# M2Sxxx register map
Vendor: Microsemi; Series: SmartFusion2; File version: 2.0.32
CPU: CM3 r2p1, little endian, MPU, no FPU, 4 interrupt priority bits
Registers are 32-bit, read-write, no defined reset value unless marked. A register's access mark holds for its fields unless they carry their own. Offsets are from the block's base; [hi:lo] are bit positions; {n}, {i} and the like mark numbered series.

## System_Registers — No description provided for this peripheral
Base 0x40038000
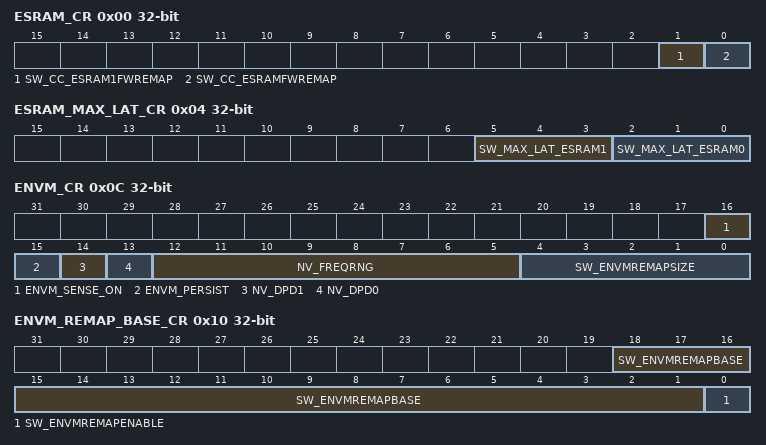
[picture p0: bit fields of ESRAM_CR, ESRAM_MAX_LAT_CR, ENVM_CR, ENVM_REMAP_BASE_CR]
0x00 ESRAM_CR — No description provided for this register
  [1] SW_CC_ESRAM1FWREMAP — No description provided for this field
  [0] SW_CC_ESRAMFWREMAP — No description provided for this field
0x04 ESRAM_MAX_LAT_CR — No description provided for this register
  [5:3] SW_MAX_LAT_ESRAM1 — No description provided for this field
  [2:0] SW_MAX_LAT_ESRAM0 — No description provided for this field
0x08 DDR_CR — No description provided for this register
  [0] SW_CC_DDRFWREMAP — No description provided for this field
0x0C ENVM_CR — No description provided for this register
  [16] ENVM_SENSE_ON — No description provided for this field
  [15] ENVM_PERSIST — No description provided for this field
  [14] NV_DPD1 — No description provided for this field
  [13] NV_DPD0 — No description provided for this field
  [12:5] NV_FREQRNG — No description provided for this field
  [4:0] SW_ENVMREMAPSIZE — No description provided for this field
0x10 ENVM_REMAP_BASE_CR — No description provided for this register
  [18:1] SW_ENVMREMAPBASE — No description provided for this field
  [0] SW_ENVMREMAPENABLE — No description provided for this field
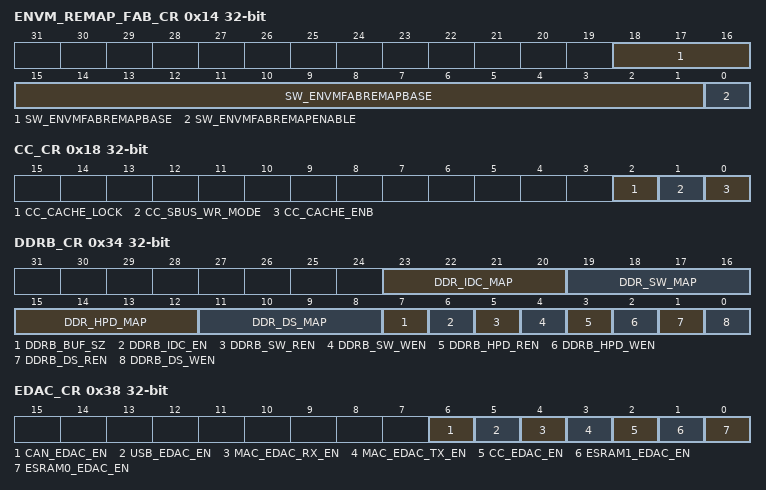
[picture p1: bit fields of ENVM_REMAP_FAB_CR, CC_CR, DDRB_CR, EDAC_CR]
0x14 ENVM_REMAP_FAB_CR — No description provided for this register
  [18:1] SW_ENVMFABREMAPBASE — No description provided for this field
  [0] SW_ENVMFABREMAPENABLE — No description provided for this field
0x18 CC_CR — No description provided for this register
  [2] CC_CACHE_LOCK — No description provided for this field
  [1] CC_SBUS_WR_MODE — No description provided for this field
  [0] CC_CACHE_ENB — No description provided for this field
0x1C CC_REGION_CR — No description provided for this register
  [3:0] CC_CACHE_REGION — No description provided for this field
0x20 CC_LOCK_BASE_ADDR_CR — No description provided for this register
  [18:0] CC_LOCK_BASEADD — No description provided for this field
0x24 CC_FLUSH_INDX_CR — No description provided for this register
  [5:0] CC_FLUSH_INDEX — No description provided for this field
0x28 DDRB_BUF_TIMER_CR — No description provided for this register
  [9:0] DDRB_TIMER — No description provided for this field
0x2C DDRB_NB_ADDR_CR — No description provided for this register
  [15:0] DDRB_NB_ADDR — No description provided for this field
0x30 DDRB_NB_SIZE_CR — No description provided for this register
  [3:0] DDRB_NB_SZ — No description provided for this field
0x34 DDRB_CR — No description provided for this register
  [23:20] DDR_IDC_MAP — No description provided for this field
  [19:16] DDR_SW_MAP — No description provided for this field
  [15:12] DDR_HPD_MAP — No description provided for this field
  [11:8] DDR_DS_MAP — No description provided for this field
  [7] DDRB_BUF_SZ — No description provided for this field
  [6] DDRB_IDC_EN — No description provided for this field
  [5] DDRB_SW_REN — No description provided for this field
  [4] DDRB_SW_WEN — No description provided for this field
  [3] DDRB_HPD_REN — No description provided for this field
  [2] DDRB_HPD_WEN — No description provided for this field
  [1] DDRB_DS_REN — No description provided for this field
  [0] DDRB_DS_WEN — No description provided for this field
0x38 EDAC_CR — No description provided for this register
  [6] CAN_EDAC_EN — No description provided for this field
  [5] USB_EDAC_EN — No description provided for this field
  [4] MAC_EDAC_RX_EN — No description provided for this field
  [3] MAC_EDAC_TX_EN — No description provided for this field
  [2] CC_EDAC_EN — No description provided for this field
  [1] ESRAM1_EDAC_EN — No description provided for this field
  [0] ESRAM0_EDAC_EN — No description provided for this field
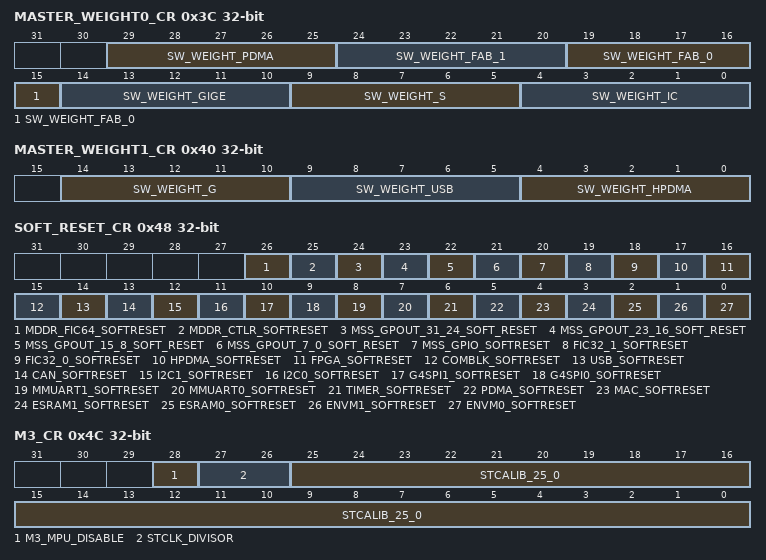
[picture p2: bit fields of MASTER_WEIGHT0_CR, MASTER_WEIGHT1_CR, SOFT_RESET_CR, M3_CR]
0x3C MASTER_WEIGHT0_CR — No description provided for this register
  [29:25] SW_WEIGHT_PDMA — No description provided for this field
  [24:20] SW_WEIGHT_FAB_1 — No description provided for this field
  [19:15] SW_WEIGHT_FAB_0 — No description provided for this field
  [14:10] SW_WEIGHT_GIGE — No description provided for this field
  [9:5] SW_WEIGHT_S — No description provided for this field
  [4:0] SW_WEIGHT_IC — No description provided for this field
0x40 MASTER_WEIGHT1_CR — No description provided for this register
  [14:10] SW_WEIGHT_G — No description provided for this field
  [9:5] SW_WEIGHT_USB — No description provided for this field
  [4:0] SW_WEIGHT_HPDMA — No description provided for this field
0x44 SOFT_IRQ_CR — No description provided for this register
  [0] SOFTINTERRUPT — No description provided for this field
0x48 SOFT_RESET_CR — No description provided for this register
  [26] MDDR_FIC64_SOFTRESET — No description provided for this field
  [25] MDDR_CTLR_SOFTRESET — No description provided for this field
  [24] MSS_GPOUT_31_24_SOFT_RESET — No description provided for this field
  [23] MSS_GPOUT_23_16_SOFT_RESET — No description provided for this field
  [22] MSS_GPOUT_15_8_SOFT_RESET — No description provided for this field
  [21] MSS_GPOUT_7_0_SOFT_RESET — No description provided for this field
  [20] MSS_GPIO_SOFTRESET — No description provided for this field
  [19] FIC32_1_SOFTRESET — No description provided for this field
  [18] FIC32_0_SOFTRESET — No description provided for this field
  [17] HPDMA_SOFTRESET — No description provided for this field
  [16] FPGA_SOFTRESET — No description provided for this field
  [15] COMBLK_SOFTRESET — No description provided for this field
  [14] USB_SOFTRESET — No description provided for this field
  [13] CAN_SOFTRESET — No description provided for this field
  [12] I2C1_SOFTRESET — No description provided for this field
  [11] I2C0_SOFTRESET — No description provided for this field
  [10] G4SPI1_SOFTRESET — No description provided for this field
  [9] G4SPI0_SOFTRESET — No description provided for this field
  [8] MMUART1_SOFTRESET — No description provided for this field
  [7] MMUART0_SOFTRESET — No description provided for this field
  [6] TIMER_SOFTRESET — No description provided for this field
  [5] PDMA_SOFTRESET — No description provided for this field
  [4] MAC_SOFTRESET — No description provided for this field
  [3] ESRAM1_SOFTRESET — No description provided for this field
  [2] ESRAM0_SOFTRESET — No description provided for this field
  [1] ENVM1_SOFTRESET — No description provided for this field
  [0] ENVM0_SOFTRESET — No description provided for this field
0x4C M3_CR — No description provided for this register
  [28] M3_MPU_DISABLE — No description provided for this field
  [27:26] STCLK_DIVISOR — No description provided for this field
  [25:0] STCALIB_25_0 — No description provided for this field
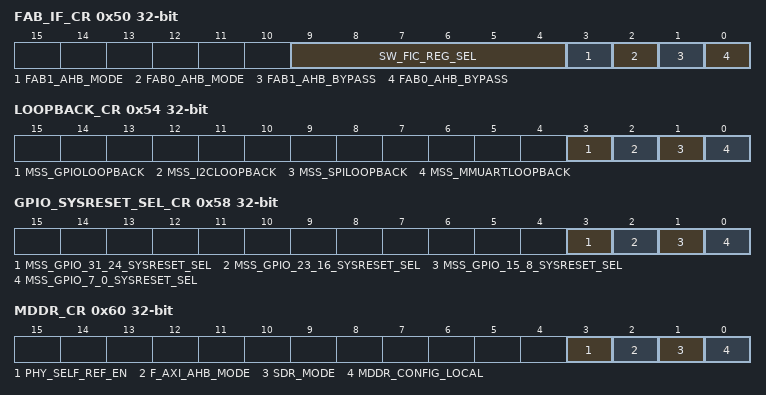
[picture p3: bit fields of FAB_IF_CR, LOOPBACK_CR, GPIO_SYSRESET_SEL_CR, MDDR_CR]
0x50 FAB_IF_CR — No description provided for this register
  [9:4] SW_FIC_REG_SEL — No description provided for this field
  [3] FAB1_AHB_MODE — No description provided for this field
  [2] FAB0_AHB_MODE — No description provided for this field
  [1] FAB1_AHB_BYPASS — No description provided for this field
  [0] FAB0_AHB_BYPASS — No description provided for this field
0x54 LOOPBACK_CR — No description provided for this register
  [3] MSS_GPIOLOOPBACK — No description provided for this field
  [2] MSS_I2CLOOPBACK — No description provided for this field
  [1] MSS_SPILOOPBACK — No description provided for this field
  [0] MSS_MMUARTLOOPBACK — No description provided for this field
0x58 GPIO_SYSRESET_SEL_CR — No description provided for this register
  [3] MSS_GPIO_31_24_SYSRESET_SEL — No description provided for this field
  [2] MSS_GPIO_23_16_SYSRESET_SEL — No description provided for this field
  [1] MSS_GPIO_15_8_SYSRESET_SEL — No description provided for this field
  [0] MSS_GPIO_7_0_SYSRESET_SEL — No description provided for this field
0x5C GPIN_SRC_SEL_CR — No description provided for this register
  [31:0] MSS_GPINSOURCE — No description provided for this field
0x60 MDDR_CR — No description provided for this register
  [3] PHY_SELF_REF_EN — No description provided for this field
  [2] F_AXI_AHB_MODE — No description provided for this field
  [1] SDR_MODE — No description provided for this field
  [0] MDDR_CONFIG_LOCAL — No description provided for this field
0x64 USB_IO_INPUT_SEL_CR — No description provided for this register
  [1:0] USB_IO_INPUT_SEL — No description provided for this field
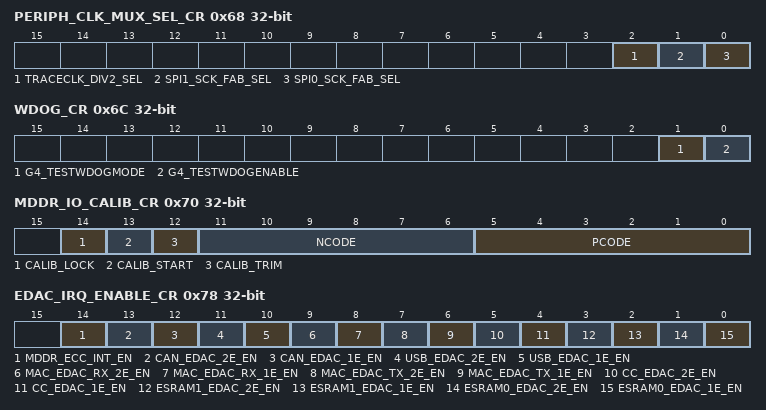
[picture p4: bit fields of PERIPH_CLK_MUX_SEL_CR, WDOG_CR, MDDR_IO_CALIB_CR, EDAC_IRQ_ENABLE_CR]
0x68 PERIPH_CLK_MUX_SEL_CR — No description provided for this register
  [2] TRACECLK_DIV2_SEL — No description provided for this field
  [1] SPI1_SCK_FAB_SEL — No description provided for this field
  [0] SPI0_SCK_FAB_SEL — No description provided for this field
0x6C WDOG_CR — No description provided for this register
  [1] G4_TESTWDOGMODE — No description provided for this field
  [0] G4_TESTWDOGENABLE — No description provided for this field
0x70 MDDR_IO_CALIB_CR — No description provided for this register
  [14] CALIB_LOCK — No description provided for this field
  [13] CALIB_START — No description provided for this field
  [12] CALIB_TRIM — No description provided for this field
  [11:6] NCODE — No description provided for this field
  [5:0] PCODE — No description provided for this field
0x74 SPARE_OUT_CR — No description provided for this register
  [15:0] MSS_SPARE_OUT — No description provided for this field
0x78 EDAC_IRQ_ENABLE_CR — No description provided for this register
  [14] MDDR_ECC_INT_EN — No description provided for this field
  [13] CAN_EDAC_2E_EN — No description provided for this field
  [12] CAN_EDAC_1E_EN — No description provided for this field
  [11] USB_EDAC_2E_EN — No description provided for this field
  [10] USB_EDAC_1E_EN — No description provided for this field
  [9] MAC_EDAC_RX_2E_EN — No description provided for this field
  [8] MAC_EDAC_RX_1E_EN — No description provided for this field
  [7] MAC_EDAC_TX_2E_EN — No description provided for this field
  [6] MAC_EDAC_TX_1E_EN — No description provided for this field
  [5] CC_EDAC_2E_EN — No description provided for this field
  [4] CC_EDAC_1E_EN — No description provided for this field
  [3] ESRAM1_EDAC_2E_EN — No description provided for this field
  [2] ESRAM1_EDAC_1E_EN — No description provided for this field
  [1] ESRAM0_EDAC_2E_EN — No description provided for this field
  [0] ESRAM0_EDAC_1E_EN — No description provided for this field
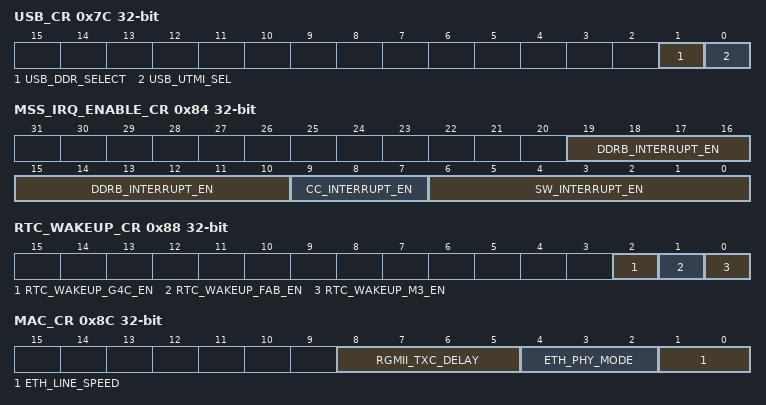
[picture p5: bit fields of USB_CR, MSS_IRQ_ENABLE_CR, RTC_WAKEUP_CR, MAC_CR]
0x7C USB_CR — No description provided for this register
  [1] USB_DDR_SELECT — No description provided for this field
  [0] USB_UTMI_SEL — No description provided for this field
0x80 ESRAM_PIPELINE_CR — No description provided for this register
  [0] ESRAM_PIPELINE_ENABLE — No description provided for this field
0x84 MSS_IRQ_ENABLE_CR — No description provided for this register
  [19:10] DDRB_INTERRUPT_EN — No description provided for this field
  [9:7] CC_INTERRUPT_EN — No description provided for this field
  [6:0] SW_INTERRUPT_EN — No description provided for this field
0x88 RTC_WAKEUP_CR — No description provided for this register
  [2] RTC_WAKEUP_G4C_EN — No description provided for this field
  [1] RTC_WAKEUP_FAB_EN — No description provided for this field
  [0] RTC_WAKEUP_M3_EN — No description provided for this field
0x8C MAC_CR — No description provided for this register
  [8:5] RGMII_TXC_DELAY — No description provided for this field
  [4:2] ETH_PHY_MODE — No description provided for this field
  [1:0] ETH_LINE_SPEED — No description provided for this field
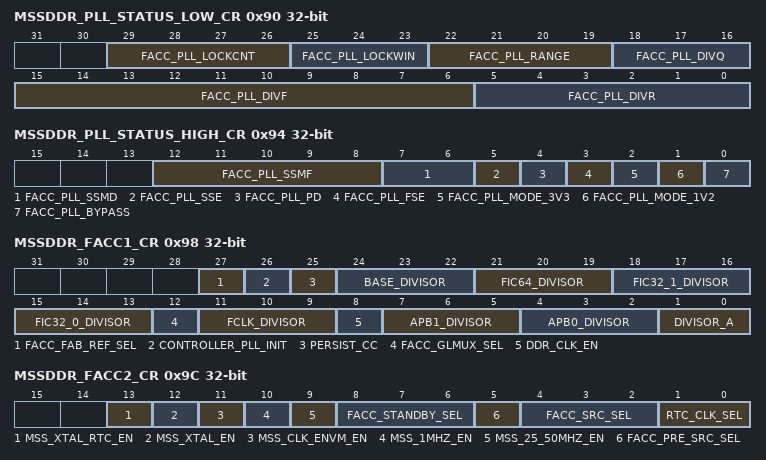
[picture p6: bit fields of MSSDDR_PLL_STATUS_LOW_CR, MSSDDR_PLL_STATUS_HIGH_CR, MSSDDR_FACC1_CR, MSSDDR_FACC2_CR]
0x90 MSSDDR_PLL_STATUS_LOW_CR — No description provided for this register
  [29:26] FACC_PLL_LOCKCNT — No description provided for this field
  [25:23] FACC_PLL_LOCKWIN — No description provided for this field
  [22:19] FACC_PLL_RANGE — No description provided for this field
  [18:16] FACC_PLL_DIVQ — No description provided for this field
  [15:6] FACC_PLL_DIVF — No description provided for this field
  [5:0] FACC_PLL_DIVR — No description provided for this field
0x94 MSSDDR_PLL_STATUS_HIGH_CR — No description provided for this register
  [12:8] FACC_PLL_SSMF — No description provided for this field
  [7:6] FACC_PLL_SSMD — No description provided for this field
  [5] FACC_PLL_SSE — No description provided for this field
  [4] FACC_PLL_PD — No description provided for this field
  [3] FACC_PLL_FSE — No description provided for this field
  [2] FACC_PLL_MODE_3V3 — No description provided for this field
  [1] FACC_PLL_MODE_1V2 — No description provided for this field
  [0] FACC_PLL_BYPASS — No description provided for this field
0x98 MSSDDR_FACC1_CR — No description provided for this register
  [27] FACC_FAB_REF_SEL — No description provided for this field
  [26] CONTROLLER_PLL_INIT — No description provided for this field
  [25] PERSIST_CC — No description provided for this field
  [24:22] BASE_DIVISOR — No description provided for this field
  [21:19] FIC64_DIVISOR — No description provided for this field
  [18:16] FIC32_1_DIVISOR — No description provided for this field
  [15:13] FIC32_0_DIVISOR — No description provided for this field
  [12] FACC_GLMUX_SEL — No description provided for this field
  [11:9] FCLK_DIVISOR — No description provided for this field
  [8] DDR_CLK_EN — No description provided for this field
  [7:5] APB1_DIVISOR — No description provided for this field
  [4:2] APB0_DIVISOR — No description provided for this field
  [1:0] DIVISOR_A — No description provided for this field
0x9C MSSDDR_FACC2_CR — No description provided for this register
  [13] MSS_XTAL_RTC_EN — No description provided for this field
  [12] MSS_XTAL_EN — No description provided for this field
  [11] MSS_CLK_ENVM_EN — No description provided for this field
  [10] MSS_1MHZ_EN — No description provided for this field
  [9] MSS_25_50MHZ_EN — No description provided for this field
  [8:6] FACC_STANDBY_SEL — No description provided for this field
  [5] FACC_PRE_SRC_SEL — No description provided for this field
  [4:2] FACC_SRC_SEL — No description provided for this field
  [1:0] RTC_CLK_SEL — No description provided for this field
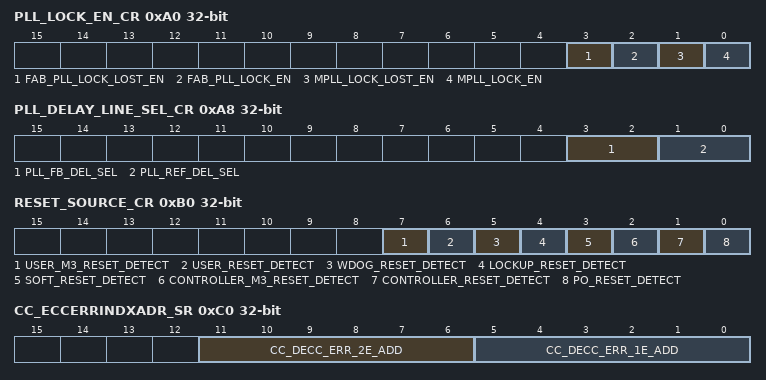
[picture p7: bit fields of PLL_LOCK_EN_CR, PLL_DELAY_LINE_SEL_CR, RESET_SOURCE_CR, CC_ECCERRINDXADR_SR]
0xA0 PLL_LOCK_EN_CR — No description provided for this register
  [3] FAB_PLL_LOCK_LOST_EN — No description provided for this field
  [2] FAB_PLL_LOCK_EN — No description provided for this field
  [1] MPLL_LOCK_LOST_EN — No description provided for this field
  [0] MPLL_LOCK_EN — No description provided for this field
0xA4 MSSDDR_CLK_CALIB_CR — No description provided for this register
  [0] FAB_CALIB_START — No description provided for this field
0xA8 PLL_DELAY_LINE_SEL_CR — No description provided for this register
  [3:2] PLL_FB_DEL_SEL — No description provided for this field
  [1:0] PLL_REF_DEL_SEL — No description provided for this field
0xAC MAC_STAT_CLRONRD_CR — No description provided for this register
  [0] MAC_STAT_CLRONRD — No description provided for this field
0xB0 RESET_SOURCE_CR — No description provided for this register
  [7] USER_M3_RESET_DETECT — No description provided for this field
  [6] USER_RESET_DETECT — No description provided for this field
  [5] WDOG_RESET_DETECT — No description provided for this field
  [4] LOCKUP_RESET_DETECT — No description provided for this field
  [3] SOFT_RESET_DETECT — No description provided for this field
  [2] CONTROLLER_M3_RESET_DETECT — No description provided for this field
  [1] CONTROLLER_RESET_DETECT — No description provided for this field
  [0] PO_RESET_DETECT — No description provided for this field
0xB4 CC_ERRRSPADDRD_SR — No description provided for this register
  [31:0] CC_DC_ERR_ADDR ro — No description provided for this field
0xB8 CC_ERRRSPADDRI_SR — No description provided for this register
  [31:0] CC_IC_ERR_ADDR ro — No description provided for this field
0xBC CC_ERRRSPADDRS_SR — No description provided for this register
  [31:0] CC_SB_ERR_ADDR ro — No description provided for this field
0xC0 CC_ECCERRINDXADR_SR — No description provided for this register
  [11:6] CC_DECC_ERR_2E_ADD ro — No description provided for this field
  [5:0] CC_DECC_ERR_1E_ADD ro — No description provided for this field
0xC4 CC_IC_MISS_CNTR_SR — No description provided for this register
  [31:0] CC_IC_MISS_CNT ro — No description provided for this field
0xC8 CC_IC_HIT_CNTR_SR — No description provided for this register
  [31:0] CC_IC_HIT_CNT ro — No description provided for this field
0xCC CC_DC_MISS_CNTR_SR — No description provided for this register
  [31:0] CC_DC_MISS_CNT ro — No description provided for this field
0xD0 CC_DC_HIT_CNTR_CR — No description provided for this register
  [31:0] CC_DC_HIT_CNT ro — No description provided for this field
0xD4 CC_IC_TRANS_CNTR_SR — No description provided for this register
  [31:0] CC_IC_TRANS_CNT ro — No description provided for this field
0xD8 CC_DC_TRANS_CNTR_SR — No description provided for this register
  [31:0] CC_DC_TRANS_CNT ro — No description provided for this field
0xDC DDRB_DS_ERR_ADR_SR — No description provided for this register
  [31:0] DDRB_DS_ERR_ADD ro — No description provided for this field
0xE0 DDRB_HPD_ERR_ADR_SR — No description provided for this register
  [31:0] DDRB_HPD_ERR_ADD ro — No description provided for this field
0xE4 DDRB_SW_ERR_ADR_SR — No description provided for this register
  [31:0] DDRB_SW_ERR_ADD ro — No description provided for this field
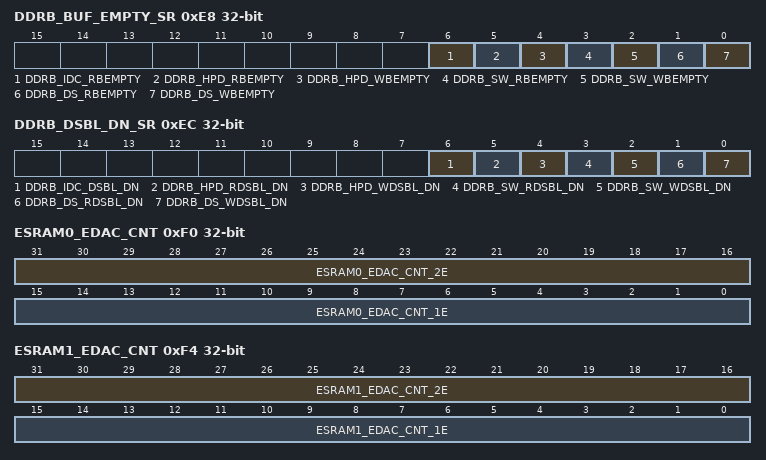
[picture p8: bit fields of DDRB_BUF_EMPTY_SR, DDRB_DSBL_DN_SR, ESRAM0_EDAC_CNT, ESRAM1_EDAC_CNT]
0xE8 DDRB_BUF_EMPTY_SR — No description provided for this register
  [6] DDRB_IDC_RBEMPTY ro — No description provided for this field
  [5] DDRB_HPD_RBEMPTY ro — No description provided for this field
  [4] DDRB_HPD_WBEMPTY ro — No description provided for this field
  [3] DDRB_SW_RBEMPTY ro — No description provided for this field
  [2] DDRB_SW_WBEMPTY ro — No description provided for this field
  [1] DDRB_DS_RBEMPTY ro — No description provided for this field
  [0] DDRB_DS_WBEMPTY ro — No description provided for this field
0xEC DDRB_DSBL_DN_SR — No description provided for this register
  [6] DDRB_IDC_DSBL_DN ro — No description provided for this field
  [5] DDRB_HPD_RDSBL_DN ro — No description provided for this field
  [4] DDRB_HPD_WDSBL_DN ro — No description provided for this field
  [3] DDRB_SW_RDSBL_DN ro — No description provided for this field
  [2] DDRB_SW_WDSBL_DN ro — No description provided for this field
  [1] DDRB_DS_RDSBL_DN ro — No description provided for this field
  [0] DDRB_DS_WDSBL_DN ro — No description provided for this field
0xF0 ESRAM0_EDAC_CNT — No description provided for this register
  [31:16] ESRAM0_EDAC_CNT_2E ro — No description provided for this field
  [15:0] ESRAM0_EDAC_CNT_1E ro — No description provided for this field
0xF4 ESRAM1_EDAC_CNT — No description provided for this register
  [31:16] ESRAM1_EDAC_CNT_2E ro — No description provided for this field
  [15:0] ESRAM1_EDAC_CNT_1E ro — No description provided for this field
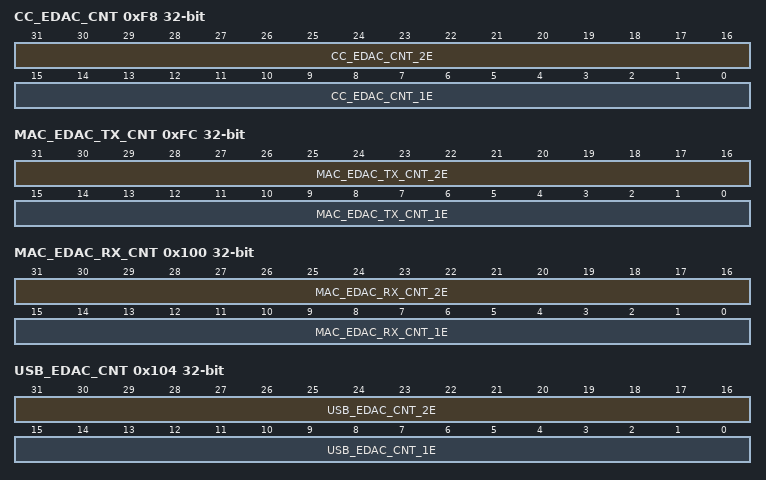
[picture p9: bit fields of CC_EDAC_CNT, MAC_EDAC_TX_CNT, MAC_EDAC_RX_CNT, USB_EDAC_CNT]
0xF8 CC_EDAC_CNT — No description provided for this register
  [31:16] CC_EDAC_CNT_2E ro — No description provided for this field
  [15:0] CC_EDAC_CNT_1E ro — No description provided for this field
0xFC MAC_EDAC_TX_CNT — No description provided for this register
  [31:16] MAC_EDAC_TX_CNT_2E ro — No description provided for this field
  [15:0] MAC_EDAC_TX_CNT_1E ro — No description provided for this field
0x100 MAC_EDAC_RX_CNT — No description provided for this register
  [31:16] MAC_EDAC_RX_CNT_2E ro — No description provided for this field
  [15:0] MAC_EDAC_RX_CNT_1E ro — No description provided for this field
0x104 USB_EDAC_CNT — No description provided for this register
  [31:16] USB_EDAC_CNT_2E ro — No description provided for this field
  [15:0] USB_EDAC_CNT_1E ro — No description provided for this field
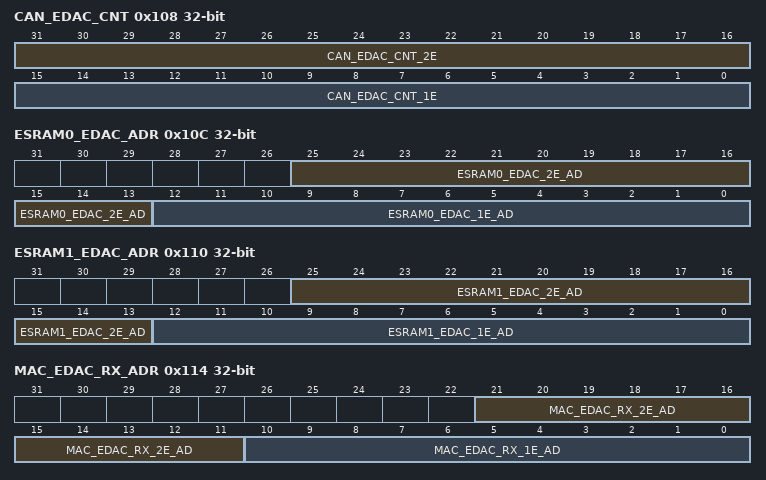
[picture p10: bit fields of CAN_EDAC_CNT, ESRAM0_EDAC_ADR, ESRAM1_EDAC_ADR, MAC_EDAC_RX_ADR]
0x108 CAN_EDAC_CNT — No description provided for this register
  [31:16] CAN_EDAC_CNT_2E ro — No description provided for this field
  [15:0] CAN_EDAC_CNT_1E ro — No description provided for this field
0x10C ESRAM0_EDAC_ADR — No description provided for this register
  [25:13] ESRAM0_EDAC_2E_AD ro — No description provided for this field
  [12:0] ESRAM0_EDAC_1E_AD ro — No description provided for this field
0x110 ESRAM1_EDAC_ADR — No description provided for this register
  [25:13] ESRAM1_EDAC_2E_AD ro — No description provided for this field
  [12:0] ESRAM1_EDAC_1E_AD ro — No description provided for this field
0x114 MAC_EDAC_RX_ADR — No description provided for this register
  [21:11] MAC_EDAC_RX_2E_AD ro — No description provided for this field
  [10:0] MAC_EDAC_RX_1E_AD ro — No description provided for this field
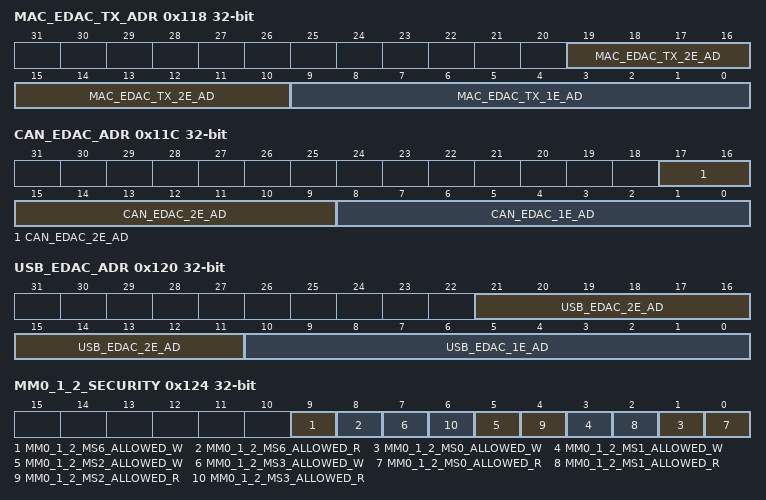
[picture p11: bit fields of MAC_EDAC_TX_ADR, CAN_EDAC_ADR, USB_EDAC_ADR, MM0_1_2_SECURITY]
0x118 MAC_EDAC_TX_ADR — No description provided for this register
  [19:10] MAC_EDAC_TX_2E_AD ro — No description provided for this field
  [9:0] MAC_EDAC_TX_1E_AD ro — No description provided for this field
0x11C CAN_EDAC_ADR — No description provided for this register
  [17:9] CAN_EDAC_2E_AD ro — No description provided for this field
  [8:0] CAN_EDAC_1E_AD ro — No description provided for this field
0x120 USB_EDAC_ADR — No description provided for this register
  [21:11] USB_EDAC_2E_AD ro — No description provided for this field
  [10:0] USB_EDAC_1E_AD ro — No description provided for this field
0x124 MM0_1_2_SECURITY — No description provided for this register
  [9] MM0_1_2_MS6_ALLOWED_W — No description provided for this field
  [8] MM0_1_2_MS6_ALLOWED_R — No description provided for this field
  [2n+1] MM0_1_2_MS{n}_ALLOWED_W (n=0..3) — No description provided for this field
  [2n] MM0_1_2_MS{n}_ALLOWED_R (n=0..3) — No description provided for this field
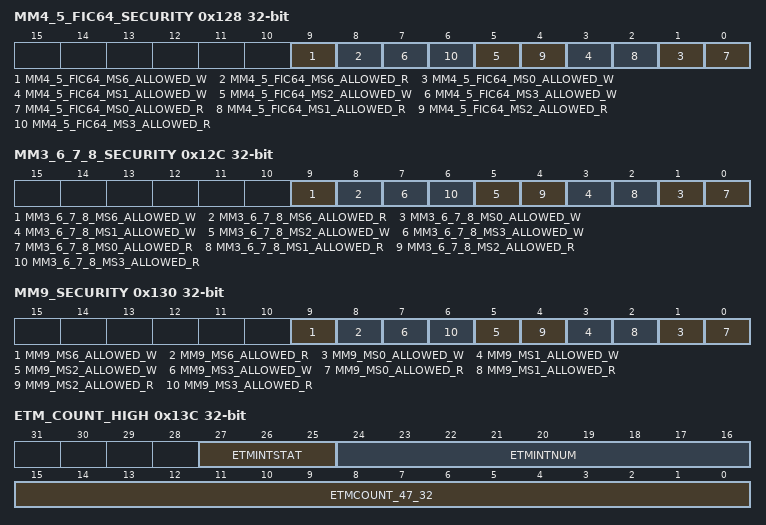
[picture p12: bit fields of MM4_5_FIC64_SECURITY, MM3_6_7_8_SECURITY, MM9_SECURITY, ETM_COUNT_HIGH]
0x128 MM4_5_FIC64_SECURITY — No description provided for this register
  [9] MM4_5_FIC64_MS6_ALLOWED_W — No description provided for this field
  [8] MM4_5_FIC64_MS6_ALLOWED_R — No description provided for this field
  [2n+1] MM4_5_FIC64_MS{n}_ALLOWED_W (n=0..3) — No description provided for this field
  [2n] MM4_5_FIC64_MS{n}_ALLOWED_R (n=0..3) — No description provided for this field
0x12C MM3_6_7_8_SECURITY — No description provided for this register
  [9] MM3_6_7_8_MS6_ALLOWED_W — No description provided for this field
  [8] MM3_6_7_8_MS6_ALLOWED_R — No description provided for this field
  [2n+1] MM3_6_7_8_MS{n}_ALLOWED_W (n=0..3) — No description provided for this field
  [2n] MM3_6_7_8_MS{n}_ALLOWED_R (n=0..3) — No description provided for this field
0x130 MM9_SECURITY — No description provided for this register
  [9] MM9_MS6_ALLOWED_W — No description provided for this field
  [8] MM9_MS6_ALLOWED_R — No description provided for this field
  [2n+1] MM9_MS{n}_ALLOWED_W (n=0..3) — No description provided for this field
  [2n] MM9_MS{n}_ALLOWED_R (n=0..3) — No description provided for this field
0x134 M3_SR — No description provided for this register
  [7:0] CURRPRI ro — No description provided for this field
0x138 ETM_COUNT_LOW — No description provided for this register
  [31:0] ETMCOUNT_31_0 ro — No description provided for this field
0x13C ETM_COUNT_HIGH — No description provided for this register
  [27:25] ETMINTSTAT ro — No description provided for this field
  [24:16] ETMINTNUM ro — No description provided for this field
  [15:0] ETMCOUNT_47_32 ro — No description provided for this field
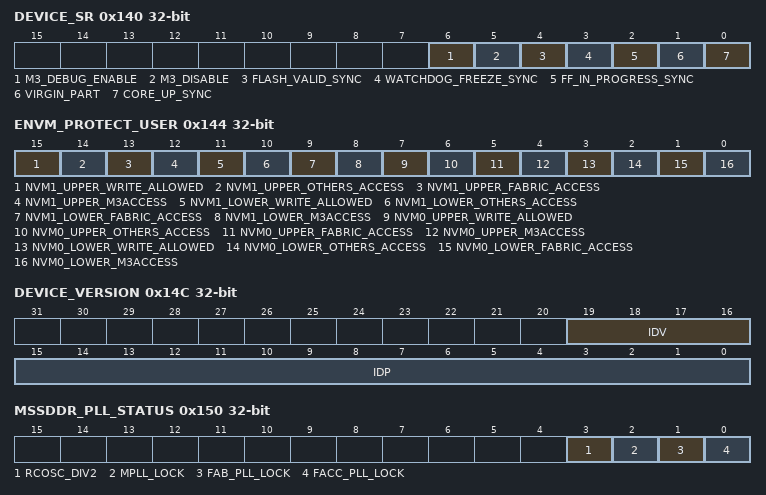
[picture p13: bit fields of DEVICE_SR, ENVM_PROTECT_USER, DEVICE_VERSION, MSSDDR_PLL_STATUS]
0x140 DEVICE_SR — No description provided for this register
  [6] M3_DEBUG_ENABLE ro — No description provided for this field
  [5] M3_DISABLE ro — No description provided for this field
  [4] FLASH_VALID_SYNC ro — No description provided for this field
  [3] WATCHDOG_FREEZE_SYNC ro — No description provided for this field
  [2] FF_IN_PROGRESS_SYNC ro — No description provided for this field
  [1] VIRGIN_PART ro — No description provided for this field
  [0] CORE_UP_SYNC ro — No description provided for this field
0x144 ENVM_PROTECT_USER — No description provided for this register
  [15] NVM1_UPPER_WRITE_ALLOWED — No description provided for this field
  [14] NVM1_UPPER_OTHERS_ACCESS — No description provided for this field
  [13] NVM1_UPPER_FABRIC_ACCESS — No description provided for this field
  [12] NVM1_UPPER_M3ACCESS — No description provided for this field
  [11] NVM1_LOWER_WRITE_ALLOWED — No description provided for this field
  [10] NVM1_LOWER_OTHERS_ACCESS — No description provided for this field
  [9] NVM1_LOWER_FABRIC_ACCESS — No description provided for this field
  [8] NVM1_LOWER_M3ACCESS — No description provided for this field
  [7] NVM0_UPPER_WRITE_ALLOWED — No description provided for this field
  [6] NVM0_UPPER_OTHERS_ACCESS — No description provided for this field
  [5] NVM0_UPPER_FABRIC_ACCESS — No description provided for this field
  [4] NVM0_UPPER_M3ACCESS — No description provided for this field
  [3] NVM0_LOWER_WRITE_ALLOWED — No description provided for this field
  [2] NVM0_LOWER_OTHERS_ACCESS — No description provided for this field
  [1] NVM0_LOWER_FABRIC_ACCESS — No description provided for this field
  [0] NVM0_LOWER_M3ACCESS — No description provided for this field
0x148 G4C_ENVM_STATUS — No description provided for this register
  [0] CODE_SHADOW_EN — No description provided for this field
0x14C DEVICE_VERSION — No description provided for this register
  [19:16] IDV ro — No description provided for this field
  [15:0] IDP ro — No description provided for this field
0x150 MSSDDR_PLL_STATUS — No description provided for this register
  [3] RCOSC_DIV2 ro — No description provided for this field
  [2] MPLL_LOCK ro — No description provided for this field
  [1] FAB_PLL_LOCK ro — No description provided for this field
  [0] FACC_PLL_LOCK ro — No description provided for this field
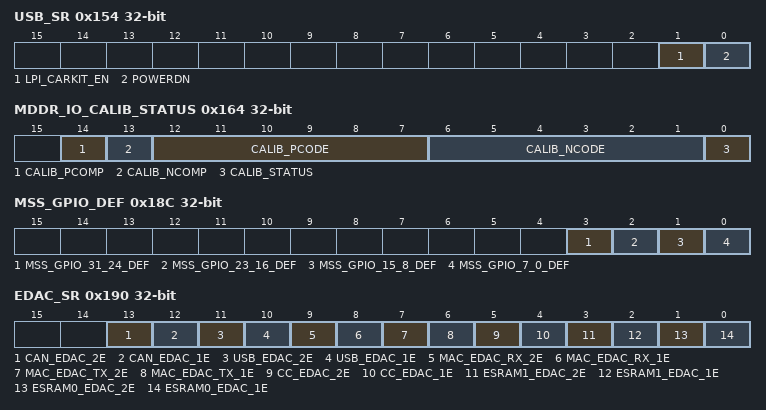
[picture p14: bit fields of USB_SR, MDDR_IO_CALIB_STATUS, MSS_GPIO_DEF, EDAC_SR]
0x154 USB_SR — No description provided for this register
  [1] LPI_CARKIT_EN ro — No description provided for this field
  [0] POWERDN ro — No description provided for this field
0x158 ENVM_SR — No description provided for this register
  [1:0] ENVM_BUSY ro — No description provided for this field
0x15C SPARE_IN — No description provided for this register
  [15:0] MSS_SPARE_IN ro — No description provided for this field
0x160 DDRB_STATUS — No description provided for this register
  [31:0] DDRB_DEBUG_STATUS ro — No description provided for this field
0x164 MDDR_IO_CALIB_STATUS — No description provided for this register
  [14] CALIB_PCOMP ro — No description provided for this field
  [13] CALIB_NCOMP ro — No description provided for this field
  [12:7] CALIB_PCODE ro — No description provided for this field
  [6:1] CALIB_NCODE ro — No description provided for this field
  [0] CALIB_STATUS ro — No description provided for this field
0x168 MSSDDR_CLK_CALIB_STATUS — No description provided for this register
  [0] FAB_CALIB_FAIL ro — No description provided for this field
0x16C WDOGLOAD — No description provided for this register
  [25:0] G4_TESTWDOGLOAD — No description provided for this field
0x170 WDOGMVRP — No description provided for this register
  [31:0] G4_TESTWDOGMVRP — No description provided for this field
{0x174+4i} USERCONFIG{i} (i=0..3) — No description provided for this register
  [31:0] CONFIG_REG{i} — No description provided for this field
0x184 FAB_PROT_SIZE — No description provided for this register
  [4:0] SW_PROTREGIONSIZE — No description provided for this field
0x188 FAB_PROT_BASE — No description provided for this register
  [31:0] SW_PROTREGIONBASE — No description provided for this field
0x18C MSS_GPIO_DEF — No description provided for this register
  [3] MSS_GPIO_31_24_DEF — No description provided for this field
  [2] MSS_GPIO_23_16_DEF — No description provided for this field
  [1] MSS_GPIO_15_8_DEF — No description provided for this field
  [0] MSS_GPIO_7_0_DEF — No description provided for this field
0x190 EDAC_SR — No description provided for this register
  [13] CAN_EDAC_2E — No description provided for this field
  [12] CAN_EDAC_1E — No description provided for this field
  [11] USB_EDAC_2E — No description provided for this field
  [10] USB_EDAC_1E — No description provided for this field
  [9] MAC_EDAC_RX_2E — No description provided for this field
  [8] MAC_EDAC_RX_1E — No description provided for this field
  [7] MAC_EDAC_TX_2E — No description provided for this field
  [6] MAC_EDAC_TX_1E — No description provided for this field
  [5] CC_EDAC_2E — No description provided for this field
  [4] CC_EDAC_1E — No description provided for this field
  [3] ESRAM1_EDAC_2E — No description provided for this field
  [2] ESRAM1_EDAC_1E — No description provided for this field
  [1] ESRAM0_EDAC_2E — No description provided for this field
  [0] ESRAM0_EDAC_1E — No description provided for this field
0x194 MSS_INTERNAL_SR — No description provided for this register
  [6] FIC64_INT — No description provided for this field
  [5] MDDR_ECC_INT — No description provided for this field
  [4] MDDR_IO_CALIB_INT — No description provided for this field
  [3] FAB_PLL_LOCKLOST_INT — No description provided for this field
  [2] FAB_PLL_LOCK_INT — No description provided for this field
  [1] MPLL_LOCKLOST_INT — No description provided for this field
  [0] MPLL_LOCK_INT — No description provided for this field
0x198 MSS_EXTERNAL_SR — No description provided for this register
  [20:18] CC_HRESP_ERR — No description provided for this field
  [17] DDRB_LOCK_MID — No description provided for this field
  [16] DDRB_LCKOUT — No description provided for this field
  [15] DDRB_HPD_WR_ERR — No description provided for this field
  [14] DDRB_SW_WR_ERR — No description provided for this field
  [13] DDRB_DS_WR_ERR — No description provided for this field
  [12:7] DDRB_RDWR_ERR_REG — No description provided for this field
  [6:0] SW_ERRORSTATUS — No description provided for this field
0x19C WDOGTIMEOUTEVENT — No description provided for this register
  [0] WDOGTIMEOUTEVENT — No description provided for this field
0x1A0 CLR_MSS_COUNTERS — No description provided for this register
  [5] CC_DC_TRANS_CNTCLR — No description provided for this field
  [4] CC_IC_TRANS_CNTCLR — No description provided for this field
  [3] CC_DC_HIT_CNTCLR — No description provided for this field
  [2] CC_DC_MISS_CNTCLR — No description provided for this field
  [1] CC_IC_HIT_CNTCLR — No description provided for this field
  [0] CC_IC_MISS_CNTCLR — No description provided for this field
0x1A4 CLR_EDAC_COUNTERS — No description provided for this register
  [13] CAN_EDAC_CNTCLR_2E — No description provided for this field
  [12] CAN_EDAC_CNTCLR_1E — No description provided for this field
  [11] USB_EDAC_CNTCLR_2E — No description provided for this field
  [10] USB_EDAC_CNTCLR_1E — No description provided for this field
  [9] MAC_EDAC_RX_CNTCLR_2E — No description provided for this field
  [8] MAC_EDAC_RX_CNTCLR_1E — No description provided for this field
  [7] MAC_EDAC_TX_CNTCLR_2E — No description provided for this field
  [6] MAC_EDAC_TX_CNTCLR_1E — No description provided for this field
  [5] CC_EDAC_CNTCLR_2E — No description provided for this field
  [4] CC_EDAC_CNTCLR_1E — No description provided for this field
  [3] ESRAM1_EDAC_CNTCLR_2E — No description provided for this field
  [2] ESRAM1_EDAC_CNTCLR_1E — No description provided for this field
  [1] ESRAM0_EDAC_CNTCLR_2E — No description provided for this field
  [0] ESRAM0_EDAC_CNTCLR_1E — No description provided for this field
0x1A8 FLUSH_CR — No description provided for this register
  [8] DDRB_INVALID_IDC — No description provided for this field
  [7] DDRB_INVALID_HPD — No description provided for this field
  [6] DDRB_INVALID_SW — No description provided for this field
  [5] DDRB_INVALID_DS — No description provided for this field
  [4] DDRB_FLSHSW — No description provided for this field
  [3] DDRB_FLSHHPD — No description provided for this field
  [2] DDRB_FLSHDS — No description provided for this field
  [1] CC_FLUSH_CHLINE — No description provided for this field
  [0] CC_FLUSH_CACHE — No description provided for this field
0x1AC MAC_STAT_CLR_CR — No description provided for this register
  [0] MAC_STAT_CLR — No description provided for this field
{0x1B0+4i} IOMUXCELL_{i}_CONFIG (i=0..56) — No description provided for this register
  [9:7] MSS_IOMUXSEL5_{i} — No description provided for this field
  [6:4] MSS_IOMUXSEL4_{i} — No description provided for this field
  [n] MSS_IOMUXSEL{n}_{i} (n=0..3) — No description provided for this field
0x294 NVM_PROTECT_FACTORY — No description provided for this register
  [15] NVM1F_UPPER_WRITE_ALLOWED — No description provided for this field
  [14] NVM1F_UPPER_OTHERS_ACCESS — No description provided for this field
  [13] NVM1F_UPPER_FABRIC_ACCESS — No description provided for this field
  [12] NVM1F_UPPER_M3ACCESS — No description provided for this field
  [11] NVM1F_LOWER_WRITE_ALLOWED — No description provided for this field
  [10] NVM1F_LOWER_OTHERS_ACCESS — No description provided for this field
  [9] NVM1F_LOWER_FABRIC_ACCESS — No description provided for this field
  [8] NVM1F_LOWER_M3ACCESS — No description provided for this field
  [7] NVM0F_UPPER_WRITE_ALLOWED — No description provided for this field
  [6] NVM0F_UPPER_OTHERS_ACCESS — No description provided for this field
  [5] NVM0F_UPPER_FABRIC_ACCESS — No description provided for this field
  [4] NVM0F_UPPER_M3ACCESS — No description provided for this field
  [3] NVM0F_LOWER_WRITE_ALLOWED — No description provided for this field
  [2] NVM0F_LOWER_OTHERS_ACCESS — No description provided for this field
  [1] NVM0F_LOWER_FABRIC_ACCESS — No description provided for this field
  [0] NVM0F_LOWER_M3ACCESS — No description provided for this field
0x298 DEVICE_STATUS_FIXED — No description provided for this register
  [6] FIC32_1_DISABLE — No description provided for this field
  [5:4] ENVM_BLOCK_SIZE — No description provided for this field
  [3] ENVM1_PRESENT — No description provided for this field
  [2] CAN_ALLOWED — No description provided for this field
  [1] M3_ALLOWED — No description provided for this field
  [0] G4_FACTORY_TEST_MODE — No description provided for this field
0x29C MBIST_ES0 — No description provided for this register
  [27:26] MBIST_ES0_COUNT — No description provided for this field
  [25:13] MBIST_ES0_ADDR1 — No description provided for this field
  [12:0] MBIST_ES0_ADDR0 — No description provided for this field
0x2A0 MBIST_ES1 — No description provided for this register
  [27:26] MBIST_ES1_COUNT — No description provided for this field
  [25:13] MBIST_ES1_ADDR1 — No description provided for this field
  [12:0] MBIST_ES1_ADDR0 — No description provided for this field
0x2A4 MSDDR_PLL_STAUS_1 — No description provided for this register
  [0] PLL_TEST_MODE — No description provided for this field
0x2A8 REDUNDANCY_ESRAM0 — No description provided for this register
  [25:13] RED_ESRAM0_ADDR1 — No description provided for this field
  [12:0] RED_ESRAM0_ADDR0 — No description provided for this field
0x2AC REDUNDANCY_ESRAM1 — No description provided for this register
  [25:13] RED_ESRAM1_ADDR1 — No description provided for this field
  [12:0] RED_ESRAM1_ADDR0 — No description provided for this field
0x2B0 SERDESIF — No description provided for this register
  [1] SERDESIF1_GEN2 — No description provided for this field
  [0] SERDESIF0_GEN2 — No description provided for this field
